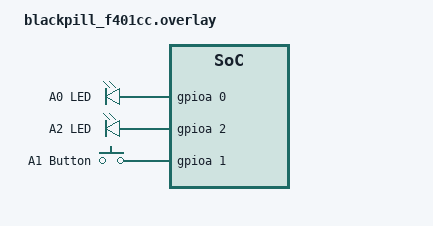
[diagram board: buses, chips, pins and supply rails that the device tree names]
/ {
	aliases {
		leda0 = &led0;
		leda2 = &led2;
		buttona1 = &button0;
	};

	leds {
		compatible = "gpio-leds";

		led0: led_0 {
			gpios = <&gpioa 0 GPIO_ACTIVE_HIGH>;
			label = "A0 LED";
		};

		led2: led_2 {
			gpios = <&gpioa 2 GPIO_ACTIVE_HIGH>;
			label = "A2 LED";
		};
	};

	buttons {
		compatible = "gpio-keys";

		button0: button_0 {
			gpios = <&gpioa 1 GPIO_ACTIVE_HIGH>;
			label = "A1 Button";
		};
	};
};
